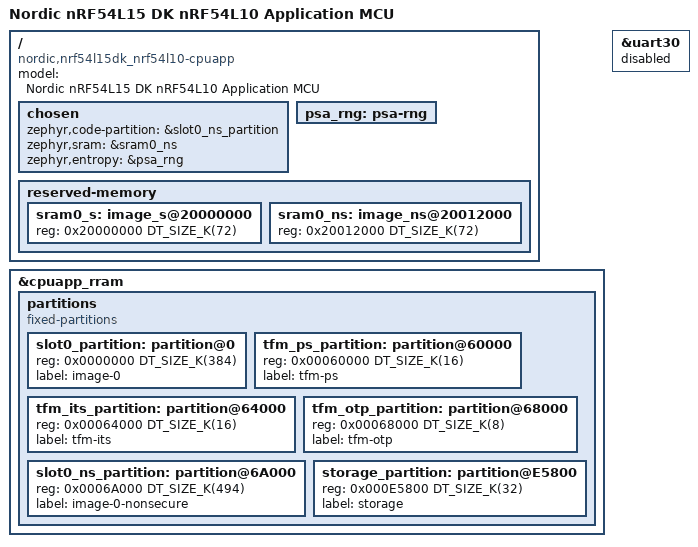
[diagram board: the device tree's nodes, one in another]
/*
 * Copyright (c) 2025 Nordic Semiconductor ASA
 *
 * SPDX-License-Identifier: Apache-2.0
 */

/dts-v1/;

#define USE_NON_SECURE_ADDRESS_MAP 1

#include <nordic/nrf54l10_cpuapp.dtsi>
#include "nrf54l_05_10_15_cpuapp_common.dtsi"

/ {
	compatible = "nordic,nrf54l15dk_nrf54l10-cpuapp";
	model = "Nordic nRF54L15 DK nRF54L10 Application MCU";

	chosen {
		zephyr,code-partition = &slot0_ns_partition;
		zephyr,sram = &sram0_ns;
		zephyr,entropy = &psa_rng;
	};

	/delete-node/ rng;

	psa_rng: psa-rng {
		status = "okay";
	};
};

/ {
	/*
	 * Default SRAM planning when building for nRF54L10 with ARM TrustZone-M support.
	 * - Lowest 72 kB SRAM allocated to Secure image (sram0_s).
	 * - Upper 72 kB SRAM allocated to Non-Secure image (sram0_ns).
	 *
	 * nRF54L10 has 192 kB of volatile memory (SRAM) but the last 42kB are reserved for
	 * the FLPR MCU.
	 * This static layout needs to be the same with the upstream TF-M layout in the
	 * header flash_layout.h of the relevant platform. Any updates in the layout
	 * needs to happen both in the flash_layout.h and in this file at the same time.
	 */
	reserved-memory {
		ranges;
		#address-cells = <1>;
		#size-cells = <1>;

		sram0_s: image_s@20000000 {
			/* Secure image memory */
			reg = <0x20000000 DT_SIZE_K(72)>;
		};

		sram0_ns: image_ns@20012000 {
			/* Non-Secure image memory */
			reg = <0x20012000 DT_SIZE_K(72)>;
		};
	};
};

&cpuapp_rram {
	partitions {
		compatible = "fixed-partitions";
		#address-cells = <1>;
		#size-cells = <1>;

		/* nRF54L10 has 1012 kB of non volatile memory (RRAM) but the
		 * last 62kB are reserved for the FLPR MCU.
		 *
		 * This static layout needs to be the same with the upstream TF-M layout in the
		 * header flash_layout.h of the relevant platform. Any updates in the layout
		 * needs to happen both in the flash_layout.h and in this file at the same time.
		 */
		slot0_partition: partition@0 {
			reg = <0x0000000 DT_SIZE_K(384)>;
			label = "image-0";
		};

		tfm_ps_partition: partition@60000 {
			reg = <0x00060000 DT_SIZE_K(16)>;
			label = "tfm-ps";
		};

		tfm_its_partition: partition@64000 {
			reg = <0x00064000 DT_SIZE_K(16)>;
			label = "tfm-its";
		};

		tfm_otp_partition: partition@68000 {
			reg = <0x00068000 DT_SIZE_K(8)>;
			label = "tfm-otp";
		};

		slot0_ns_partition: partition@6A000 {
			reg = <0x0006A000 DT_SIZE_K(494)>;
			label = "image-0-nonsecure";
		};

		storage_partition: partition@E5800 {
			reg = <0x000E5800 DT_SIZE_K(32)>;
			label = "storage";
		};
	};
};

&uart30 {
	/* Disable so that TF-M can use this UART */
	status = "disabled";
};
